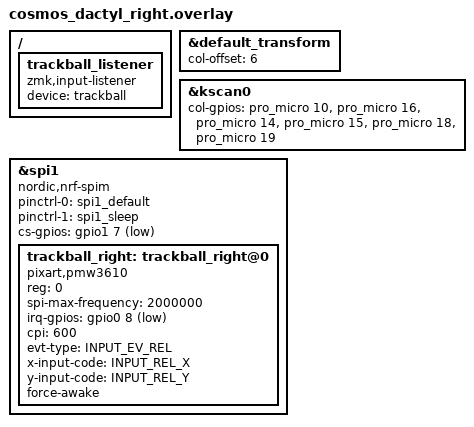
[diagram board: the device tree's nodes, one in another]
/*
 * Copyright (c) 2020 Ryan Cross
 *
 * SPDX-License-Identifier: MIT
 */

#include "cosmos_dactyl.dtsi"

&default_transform {
    col-offset = <6>;
};

&kscan0 {
    col-gpios
        = <&pro_micro 10 GPIO_ACTIVE_HIGH>
        , <&pro_micro 16 GPIO_ACTIVE_HIGH>
        , <&pro_micro 14 GPIO_ACTIVE_HIGH>
        , <&pro_micro 15 GPIO_ACTIVE_HIGH>
        , <&pro_micro 18 GPIO_ACTIVE_HIGH>
        , <&pro_micro 19 GPIO_ACTIVE_HIGH>
        ;
};

#include <input/processors.dtsi>

#include <zephyr/dt-bindings/input/input-event-codes.h>

&spi1 {
    status = "okay";
    compatible = "nordic,nrf-spim";
    pinctrl-0 = <&spi1_default>;
    pinctrl-1 = <&spi1_sleep>;
    pinctrl-names = "default", "sleep";
    cs-gpios = <&gpio1 7 GPIO_ACTIVE_LOW>;

    trackball_right: trackball_right@0 {
        status = "okay";
        compatible = "pixart,pmw3610";
        reg = <0>;
        spi-max-frequency = <2000000>;
        irq-gpios = <&gpio0 8 (GPIO_ACTIVE_LOW | GPIO_PULL_UP)>;
        cpi = <600>;
        evt-type = <INPUT_EV_REL>;
        x-input-code = <INPUT_REL_X>;
        y-input-code = <INPUT_REL_Y>;

        force-awake;
        /* keep the sensor awake while ZMK activity state is ACTIVE,
           fallback to normal downshift mode after ZMK goes into IDLE / SLEEP mode.
           thus, the sensor would be a `wakeup-source` */
    };
};

/ {
  trackball_listener {
    compatible = "zmk,input-listener";
    device = <&trackball>;
  };
};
